# CY8C5868AXI_LP035 register map
File version: 0.1
Registers are 8-bit, read-write, no defined reset value unless marked. A register's access mark holds for its fields unless they carry their own. Offsets are from the block's base; [hi:lo] are bit positions; 'fields as' and 'values as' point back to an identical list.

## PWM_10
Base 0x00000000
0x4000642C PWM_10_COMPARE_Reg_ — UDB.D0 - Assigned Compare Value
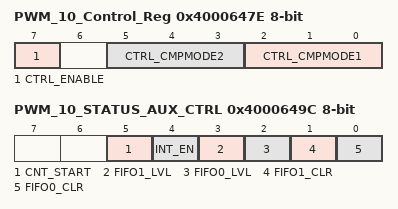
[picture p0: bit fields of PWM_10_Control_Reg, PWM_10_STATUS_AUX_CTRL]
0x4000647E PWM_10_Control_Reg — UDB Control Register - Assigned Control Register Value
  [7] CTRL_ENABLE — Enable the PWM
  [5:3] CTRL_CMPMODE2 — Compare mode 2
  [2:0] CTRL_CMPMODE1 — Compare mode 1
0x4000649C PWM_10_STATUS_AUX_CTRL — UDB Auxilliary Control Register
  [5] CNT_START — FIFO0 clear
    0=E_CNT_START0 (Disable counter); 1=E_CNT_START1 (Enable counter)
  [4] INT_EN
    0=E_INT_EN0 (Interrupt disabled); 1=E_INT_EN1 (Interrupt enabled)
  [3] FIFO1_LVL — FIFO level
    0=E_FIFO_LVL_0 (FIFO LVL: input mode: FIFO not full; output mode: FIFO not empty); 1=E_FIFO_LVL_1 (FIFO LVL: input mode: FIFO at least 1/2 empty; output mode: FIFO at least 1/2 full)
  [2] FIFO0_LVL — FIFO level
    values as FIFO1_LVL
  [1] FIFO1_CLR — FIFO1 clear
    0=E_FIFO_CLR_0 (Normal FIFO operation); 1=E_FIFO_CLR_1 (Clear FIFO state)
  [0] FIFO0_CLR — FIFO0 clear
    values as FIFO1_CLR

## PWM_11
Base 0x00000000
0x40006428 PWM_11_COMPARE_Reg_ — UDB.D0 - Assigned Compare Value
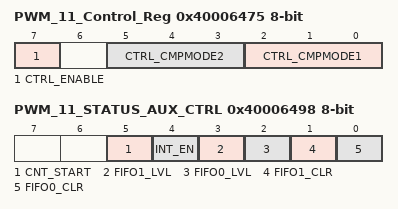
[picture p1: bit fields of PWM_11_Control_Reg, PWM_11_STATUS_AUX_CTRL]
0x40006475 PWM_11_Control_Reg — UDB Control Register - Assigned Control Register Value
  [7] CTRL_ENABLE — Enable the PWM
  [5:3] CTRL_CMPMODE2 — Compare mode 2
  [2:0] CTRL_CMPMODE1 — Compare mode 1
0x40006498 PWM_11_STATUS_AUX_CTRL — UDB Auxilliary Control Register
  [5] CNT_START — FIFO0 clear
    0=E_CNT_START0 (Disable counter); 1=E_CNT_START1 (Enable counter)
  [4] INT_EN
    0=E_INT_EN0 (Interrupt disabled); 1=E_INT_EN1 (Interrupt enabled)
  [3] FIFO1_LVL — FIFO level
    0=E_FIFO_LVL_0 (FIFO LVL: input mode: FIFO not full; output mode: FIFO not empty); 1=E_FIFO_LVL_1 (FIFO LVL: input mode: FIFO at least 1/2 empty; output mode: FIFO at least 1/2 full)
  [2] FIFO0_LVL — FIFO level
    values as FIFO1_LVL
  [1] FIFO1_CLR — FIFO1 clear
    0=E_FIFO_CLR_0 (Normal FIFO operation); 1=E_FIFO_CLR_1 (Clear FIFO state)
  [0] FIFO0_CLR — FIFO0 clear
    values as FIFO1_CLR

## PWM_7
Base 0x00000000
0x40006526 PWM_7_COMPARE_Reg_ — UDB.D0 - Assigned Compare Value
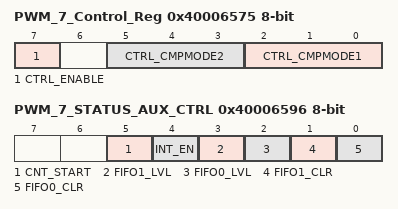
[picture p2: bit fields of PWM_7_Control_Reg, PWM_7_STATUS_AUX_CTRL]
0x40006575 PWM_7_Control_Reg — UDB Control Register - Assigned Control Register Value
  [7] CTRL_ENABLE — Enable the PWM
  [5:3] CTRL_CMPMODE2 — Compare mode 2
  [2:0] CTRL_CMPMODE1 — Compare mode 1
0x40006596 PWM_7_STATUS_AUX_CTRL — UDB Auxilliary Control Register
  [5] CNT_START — FIFO0 clear
    0=E_CNT_START0 (Disable counter); 1=E_CNT_START1 (Enable counter)
  [4] INT_EN
    0=E_INT_EN0 (Interrupt disabled); 1=E_INT_EN1 (Interrupt enabled)
  [3] FIFO1_LVL — FIFO level
    0=E_FIFO_LVL_0 (FIFO LVL: input mode: FIFO not full; output mode: FIFO not empty); 1=E_FIFO_LVL_1 (FIFO LVL: input mode: FIFO at least 1/2 empty; output mode: FIFO at least 1/2 full)
  [2] FIFO0_LVL — FIFO level
    values as FIFO1_LVL
  [1] FIFO1_CLR — FIFO1 clear
    0=E_FIFO_CLR_0 (Normal FIFO operation); 1=E_FIFO_CLR_1 (Clear FIFO state)
  [0] FIFO0_CLR — FIFO0 clear
    values as FIFO1_CLR

## PWM_6
Base 0x00000000
0x40006427 PWM_6_COMPARE_Reg_ — UDB.D0 - Assigned Compare Value
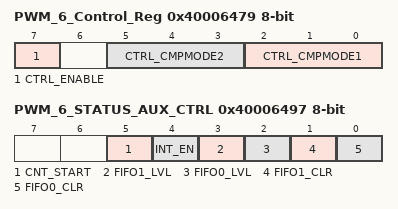
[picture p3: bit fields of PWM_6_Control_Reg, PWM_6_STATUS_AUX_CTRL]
0x40006479 PWM_6_Control_Reg — UDB Control Register - Assigned Control Register Value
  [7] CTRL_ENABLE — Enable the PWM
  [5:3] CTRL_CMPMODE2 — Compare mode 2
  [2:0] CTRL_CMPMODE1 — Compare mode 1
0x40006497 PWM_6_STATUS_AUX_CTRL — UDB Auxilliary Control Register
  [5] CNT_START — FIFO0 clear
    0=E_CNT_START0 (Disable counter); 1=E_CNT_START1 (Enable counter)
  [4] INT_EN
    0=E_INT_EN0 (Interrupt disabled); 1=E_INT_EN1 (Interrupt enabled)
  [3] FIFO1_LVL — FIFO level
    0=E_FIFO_LVL_0 (FIFO LVL: input mode: FIFO not full; output mode: FIFO not empty); 1=E_FIFO_LVL_1 (FIFO LVL: input mode: FIFO at least 1/2 empty; output mode: FIFO at least 1/2 full)
  [2] FIFO0_LVL — FIFO level
    values as FIFO1_LVL
  [1] FIFO1_CLR — FIFO1 clear
    0=E_FIFO_CLR_0 (Normal FIFO operation); 1=E_FIFO_CLR_1 (Clear FIFO state)
  [0] FIFO0_CLR — FIFO0 clear
    values as FIFO1_CLR
